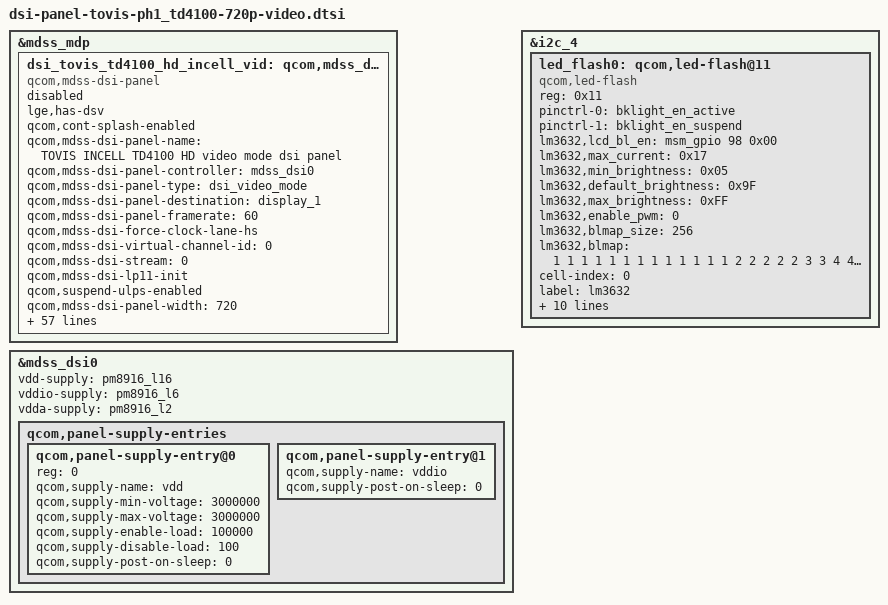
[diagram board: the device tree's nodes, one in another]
&mdss_mdp {
	dsi_tovis_td4100_hd_incell_vid: qcom,mdss_dsi_tovis_incell_td4100_hd_video{
		lge,has-dsv;
		compatible = "qcom,mdss-dsi-panel";
		status = "disable";
		qcom,cont-splash-enabled;
		qcom,mdss-dsi-panel-name = "TOVIS INCELL TD4100 HD video mode dsi panel";
		qcom,mdss-dsi-panel-controller = <&mdss_dsi0>;
		qcom,mdss-dsi-panel-type = "dsi_video_mode";
		qcom,mdss-dsi-panel-destination = "display_1";
		qcom,mdss-dsi-panel-framerate = <60>;
		qcom,mdss-dsi-force-clock-lane-hs;
		qcom,mdss-dsi-virtual-channel-id = <0>;
		qcom,mdss-dsi-stream = <0>;
		qcom,mdss-dsi-lp11-init;
		qcom,suspend-ulps-enabled;
		qcom,mdss-dsi-panel-width = <720>;
		qcom,mdss-dsi-panel-height = <1280>;
		qcom,mdss-dsi-h-front-porch = <78>;
		qcom,mdss-dsi-h-back-porch = <32>;
		qcom,mdss-dsi-h-pulse-width = <4>;
		qcom,mdss-dsi-h-sync-skew = <0>;
		qcom,mdss-dsi-v-front-porch = <127>;
		qcom,mdss-dsi-v-back-porch = <127>;
		qcom,mdss-dsi-v-pulse-width = <127>;
		qcom,mdss-dsi-h-left-border = <0>;
		qcom,mdss-dsi-h-right-border = <0>;
		qcom,mdss-dsi-v-top-border = <0>;
		qcom,mdss-dsi-v-bottom-border = <0>;
		qcom,mdss-pan-physical-width-dimension = <71>;
		qcom,mdss-pan-physical-height-dimension = <126>;
		qcom,mdss-dsi-bpp = <24>;
		qcom,mdss-dsi-color-order = "rgb_swap_rgb";
		qcom,mdss-dsi-underflow-color = <0>;
		qcom,mdss-dsi-border-color = <0>;
		qcom,mdss-dsi-on-command = [
			05 01 00 00 00 00 02
			29 00
			05 01 00 00 78 00 02
			11 00
		];
		qcom,mdss-dsi-off-command = [
			05 01 00 00 00 00 02
			28 00
			05 01 00 00 78 00 02
			10 00
		];
		qcom,mdss-dsi-lut-update-command = [
			05 01 00 00 00 00 02
			26 00
		];

		qcom,panel-reader-mode-step1-command = [
			15 01 00 00 00 00 02
			84 3C
		];
		qcom,panel-reader-mode-step2-command = [
			15 01 00 00 00 00 02
			84 58
		];
		qcom,panel-reader-mode-step3-command = [
			15 01 00 00 00 00 02
			84 70
		];
		qcom,panel-reader-mode-off-command = [
			15 01 00 00 00 00 02
			84 00
		];

		qcom,mdss-dsi-on-command-state = "dsi_lp_mode";
		qcom,mdss-dsi-off-command-state = "dsi_hs_mode";
		qcom,mdss-dsi-lut-update-command-state = "dsi_hs_mode";
		qcom,mdss-dsi-reader_mode-command-state = "dsi_hs_mode";
		qcom,mdss-dsi-h-sync-pulse = <0>;
		qcom,mdss-dsi-traffic-mode = "non_burst_sync_event";
		qcom,mdss-dsi-lane-map = "lane_map_0123";
		//qcom,mdss-dsi-hfp-power-mode;
		//qcom,mdss-dsi-hbp-power-mode;
		//qcom,mdss-dsi-hsa-power-mode;
		qcom,mdss-dsi-bllp-eof-power-mode;
		qcom,mdss-dsi-bllp-power-mode;
		qcom,mdss-dsi-lane-0-state;
		qcom,mdss-dsi-lane-1-state;
		qcom,mdss-dsi-lane-2-state;
		qcom,mdss-dsi-lane-3-state;
		qcom,mdss-dsi-panel-timings = [8B 1E 14 00 44 4A 18 22 19 03 04 00];
		qcom,mdss-dsi-t-clk-post = <0x04>;
		qcom,mdss-dsi-t-clk-pre = <0x1C>;


		qcom,mdss-dsi-bl-min-level = <1>;
		qcom,mdss-dsi-bl-max-level = <255>;
		qcom,mdss-dsi-dma-trigger = "trigger_sw";
		qcom,mdss-dsi-mdp-trigger = "none";
		//qcom,mdss-dsi-bl-pmic-control-type = "bl_ctrl_wled";
		qcom,mdss-dsi-reset-sequence = <0 10>, <1 200>;
	};
};

&mdss_dsi0 {
    vdd-supply = <&pm8916_l16>;
    vddio-supply = <&pm8916_l6>;
    vdda-supply = <&pm8916_l2>;
    qcom,panel-supply-entries {
        qcom,panel-supply-entry@0 {
            reg = <0>;
            qcom,supply-name = "vdd";
            qcom,supply-min-voltage = <3000000>;
            qcom,supply-max-voltage = <3000000>;
            qcom,supply-enable-load = <100000>;
            qcom,supply-disable-load = <100>;
            qcom,supply-post-on-sleep = <0>;
        };
        qcom,panel-supply-entry@1 {
            qcom,supply-name = "vddio";
            qcom,supply-post-on-sleep = <0>;
        };
    };
};

&i2c_4 {
	led_flash0: qcom,led-flash@11 {
				compatible                = "qcom,led-flash";
				status                    = "ok";
				reg                       = <0x11>;

				pinctrl-names = "default", "sleep";
				pinctrl-0 = <&bklight_en_active>;
				pinctrl-1 = <&bklight_en_suspend>;

				lm3632,lcd_bl_en = <&msm_gpio 98 0x00>;
				lm3632,max_current = <0x17>;
				lm3632,min_brightness = <0x05>;
				lm3632,default_brightness = <0x9F>;
				lm3632,max_brightness = <0xFF>;
				lm3632,enable_pwm = <0>;
				lm3632,blmap_size = <256>;
				lm3632,blmap = <
					/* 0  */    1   1   1   1   1   1   1   1   1   1
					/* 10 */    1   1   1   2   2   2   2   2   3   3
					/* 20 */    4   4   4   5   5   5   5   5   5   5
					/* 30 */    5   5   5   5   5   5   5   5   5   5
					/* 40 */    5   5   5   5   5   5   5   5   5   5
					/* 50 */    5   6   6   6   6   6   6   6   7   7
					/* 60 */    7   7   7   7   8   8   8   8   8   9
					/* 70 */    9   9   9   10  10  10  11  11  11  12
					/* 80 */    12  12  13  13  13  14  14  15  15  16
					/* 90 */    16  17  17  18  18  19  19  19  20  20
					/* 100 */   21  21  22  22  23  23  24  24  25  25
					/* 110 */   25  26  26  27  27  28  28  29  29  30
					/* 120 */   30  31  31  32  32  33  33  34  34  35
					/* 130 */   36  37  38  39  40  41  42  43  44  45
					/* 140 */   46  47  47  47  48  48  49  50  51  52
					/* 150 */   53  54  55  55  56  56  57  57  58  58
					/* 160 */   59  60  61  62  63  64  65  66  67  68
					/* 170 */   69  70  71  72  73  74  75  76  77  78
					/* 180 */   79  80  81  82  83  84  85  86  87  88
					/* 190 */   89  90  91  92  93  94  95  96  97  99
					/* 200 */   101 103 104 105 106 107 108 109 110 111
					/* 210 */   112 113 114 115 117 119 121 123 125 126
					/* 220 */   127 129 131 135 137 139 141 143 143 144
					/* 230 */   144 145 145 147 149 151 153 155 157 159
					/* 240 */   161 162 163 164 165 165 167 169 171 173
					/* 250 */   175 177 179 182 185 187 >;

				cell-index = <0>;
				label                   = "lm3632";
				qcom,flash-name         = "lm3632";
				qcom,slave-id           = <0x11 0x01 0x01>;
				qcom,flash-type         = <1>;              // LED_FLASH
				qcom,gpio-no-mux        = <0>;
				gpios                   = <&msm_gpio 31 0>; // FLASH_STROBE_TRIG, GPIO 31
				qcom,gpio-flash-en      = <0>;
				qcom,gpio-req-tbl-num   = <0>;
				qcom,gpio-req-tbl-flags = <0>;
				qcom,gpio-req-tbl-label = "FLASH_EN";
				qcom,cci-master = <0>;
			};
};
